# W7500x register map
Vendor: WIZnet; File version: 1.0.0
CPU: CM0 r0p0, little endian, no MPU, no FPU, 2 interrupt priority bits
Registers are 32-bit, read-write, reset 0x0 unless marked. A register's access mark holds for its fields unless they carry their own. Offsets are from the block's base; [hi:lo] are bit positions; {n}, {i} and the like mark numbered series.

## SYSCFG
Base 0x4001F000
0x00 REMAP reset not defined — Remap Control Register (R/W)
0x04 PMUCTRL reset not defined — PMU Control Register (R/W)
0x08 RESETOP reset not defined — Reset Option Register (R/W)
0x0C EMICTRL reset not defined — EMI Control Register (R/W)
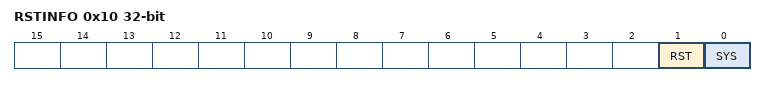
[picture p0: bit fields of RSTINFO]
0x10 RSTINFO — Reset Information Register (R/W)
  [1] RST — Interrupt Enable
  [0] SYS — Reset Request Enable

## ADC
Base 0x41000000
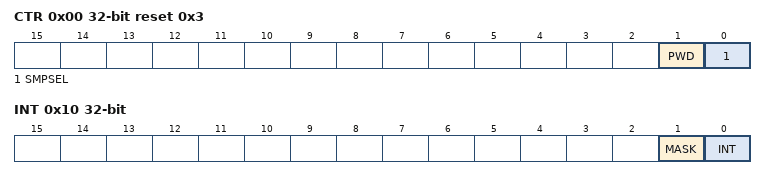
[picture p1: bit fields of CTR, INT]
0x00 CTR reset 0x3 — ADC control register
  [1] PWD — power down flag
    0=Active; 1=PowerDown
  [0] SMPSEL — Sampling mode
    0=Abnormal; 1=Normal
0x04 CHSEL — ADC channel select register
  [3:0] CHSEL — ADC Channel Select bits
    {v}=Channel{v} (v=0..7); 8=NoChannel; 15=LDOOutput1V5
0x08 START wo — ADC start register
  [0] ADC_SRT — Start ADC for conversion
    0=Ready; 1=Start (This bit clear automatically after conversion)
0x0C DATA ro — ADC conversion data register
  [11:0] ADC_DATA — ADC conversion result data
0x10 INT — ADC interrupt register
  [1] MASK — Interrupt mask signal
    0=Disable; 1=Enable
  [0] INT — ADC conversion is done of Interrupt bit
    0=Done; 1=NotDone
0x1C INTCLR wo — ADC interrupt clear register
  [0] INTCLR — ADC conversion is done of Interrupt bit
    1=Clear

## AFC_PA
Base 0x41002000
Same registers: AFC_PB 0x41002040, AFC_PC 0x41002080, AFC_PD 0x410020C0, EXTI_PA 0x41002200, EXTI_PB 0x41002240, EXTI_PC 0x41002280, EXTI_PD 0x410022C0, PADCON_PA 0x41003000, PADCON_PB 0x41003040, PADCON_PC 0x41003080, PADCON_PD 0x410030C0

## DMA
Base 0x41004000
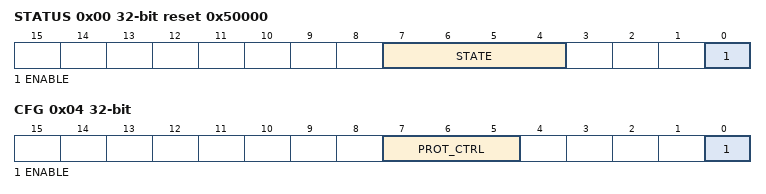
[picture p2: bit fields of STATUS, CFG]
0x00 STATUS ro reset 0x50000 — DMA status register
  [7:4] STATE — Current state of the control state machine
    0=Idle; 1=ReadingChanCtrlData; 2=ReadingSrcDataEndPtr; 3=ReadingDstDataEndPtr; 4=ReadingSrcData; 5=WritingDstData; 6=WritingChanCtrlData; 8=Stalled; 9=Done; 10=PeriphScatGathTrans
  [0] ENABLE — Enable status of the controller
    0=Disable; 1=Enable
0x04 CFG wo — DMA configuration register
  [7:5] PROT_CTRL — Set the AHB-Lite protection
  [0] ENABLE — Enable for the controller
    0=Disable; 1=Enable
0x08 CTRL_BASE_PTR — Channel Control Data Base Pointer register
  [31:8] CTRL_BASE_PTR — Pointer to the base address of the primary data structure
0x0C ALT_CTRL_BASE_PTR ro — Channel Alternate Control Data Base Pointer register
  [31:0] ALT_CTRL_BASE_PTR — Base address of the alternate data structure
0x10 WAITONREQ_STATUS ro — Channel Wait On Request Status register
  [5:0] DMA_WAITONREQ — Channel wait on request status
0x14 CHNL_SW_REQUEST wo — Channel Software Request register
  [5:0] CHNL_SW_REQUEST — Set the appropriate bit to generate a software DMA request
0x18 CHNL_USEBURST_SET — Channel UseBurst Set register
  [5:0] CHNL_USEBURST_SET — CHNL_USEBURST_SET[5:0] bits (Returns the useburst status, or disable dma_sreq[Channel-1] form generating DMA requests)
0x1C CHNL_USEBURST_CLR wo — Channel UseBurst Clear register
  [5:0] CHNL_USEBURST_CLR — CHNL_USEBURST_CLR[5:0] bits (Set the appropriate bit to enable dma_sreq[Channel-1] to generate requests)
0x20 CHNL_REQ_MASK_SET — Channel Request Mask Set register
  [5:0] CHNL_REQ_MASK_SET — CHNL_REQ_MASK_SET[5:0] bits (Returns the request mask status of dma_req[Channel-1] and dma_sreq[Channel-1], or disables the corresponding channel from generating DMA requests)
0x24 CHNL_REQ_MASK_CLR wo — Channel Request Mask Clear register
  [5:0] CHNL_REQ_MASK_CLR — CHNL_REQ_MASK_CLR[5:0] bits (Set the appropriate bit to enable DMA requests for the channel corresponding to dma_req[Channel-1] and dma_sreq[Channel-1])
0x28 CHNL_ENABLE_SET — Channel Enable Set register
  [5:0] CHNL_ENABLE_SET — CHNL_ENABLE_SET[5:0] bits (Set the appropriate bit to enable DMA requests for the channel corresponding to dma_req[Channel-1] and dma_sreq[Channel-1])
0x2C CHNL_ENABLE_CLR wo — Channel Enable Clear register
  [5:0] CHNL_ENABLE_CLR — Set the appropriate bit to disable the corresponding DMA channel
0x30 CHNL_PRI_ALT_SET — Channel Primary-Alterante Set register
  [5:0] CHNL_PRI_ALT_SET — CHNL_PRI_ALT_SET[5:0] bits (Returns the channel control data structure status, or selects the alternate data structure for the corresponding DMA channels)
0x34 CHNL_PRI_ALT_CLR wo — Channel Primary-Alterante Clear register
  [5:0] CHNL_PRI_ALT_CLR — Set the appropriate bit to select the primary data structure for the corresponding DMA channel
0x38 CHNL_PRIORITY_SET — Channel Priority Set register
  [5:0] CHNL_PRIORITY_SET — CHNL_PRIORITY_SET[5:0] bits (Returns the channel priority mask status, or set the channel priority to high)
0x3C CHNL_PRIORITY_CLR wo — Channel Priority Clear register
  [5:0] CHNL_PRIORITY_CLR — Set the appropriate bit to select the default priority level for the specified DMA channel
0x4C ERR_CLR — Bus Error Clear register
  [0] ERR_CLR — Returns the status of DMA_ERR, or set the signal LOW
    0=Low; 1=High

## GPIOA
Base 0x42000000
Same registers: GPIOB 0x43000000, GPIOC 0x44000000, GPIOD 0x45000000
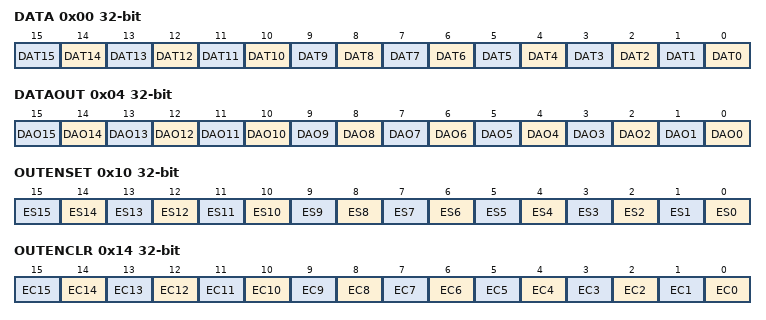
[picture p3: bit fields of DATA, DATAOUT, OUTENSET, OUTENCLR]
0x00 DATA ro
  [n] DAT{n} (n=0..15) — Port input data bit
0x04 DATAOUT — Data Output Latch register
  [n] DAO{n} (n=0..15) — Port out data bit
0x10 OUTENSET — Output Enable Set register
  [n] ES{n} (n=0..15) — sets the corresponding output enable bit, indicates the signal direction
0x14 OUTENCLR — Output Enable Clear register
  [n] EC{n} (n=0..15) — clears the output enable bit, indicates the signal direction
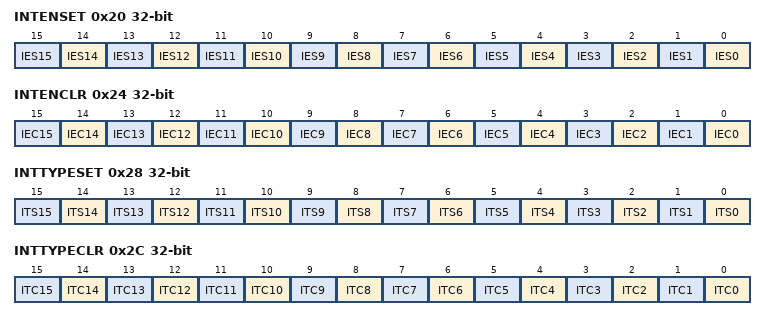
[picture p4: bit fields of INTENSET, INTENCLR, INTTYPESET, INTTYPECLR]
0x20 INTENSET — Interrupt Enable Set register
  [n] IES{n} (n=0..15) — sets the interrupt enable bit, indicates the interrupt
0x24 INTENCLR — Interrupt Enable Clear register
  [n] IEC{n} (n=0..15) — clears the interrupt enable bit, indicates the interrupt
0x28 INTTYPESET — Interrupt Type Set register
  [n] ITS{n} (n=0..15) — sets the interrupt type bit, indicates for edge or level
0x2C INTTYPECLR — Interrupt Type Clear register
  [n] ITC{n} (n=0..15) — clears the interrupt type bit, indicates for edge or level
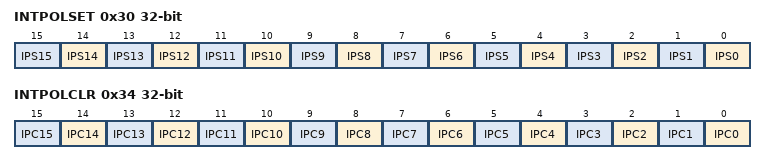
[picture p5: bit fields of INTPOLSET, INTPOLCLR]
0x30 INTPOLSET — Interrupt Polarity Set register
  [n] IPS{n} (n=0..15) — sets the interrupt polarity bit, indicates for edge or level
0x34 INTPOLCLR — Interrupt Polarity Clear register
  [n] IPC{n} (n=0..15) — clears the interrupt polarity bit, indicates for edge or level
0x38 INTSTATUS ro reset not defined — Interrupt Status register
0x38 INTCLEAR wo reset not defined — Interrupt Clear register
{0x400+4i} LB_MASKED[{i}] (i=0..255) — Lower byte Masked Access register
  [7:0] LBM — Data for lower byte access
{0x800+4i} UB_MASKED[{i}] (i=0..255) — Upper byte Masked Access register
  [15:8] HBM — Data for higher byte access
